# STMP3770 register map
Vendor: Freescale Semiconductor (NXP); Series: STMP37xx; File version: 1.0
CPU: other r0p0, little endian, no MPU, no FPU, 2 interrupt priority bits
Registers are 32-bit, read-write, reset 0x0 unless marked. A register's access mark holds for its fields unless they carry their own. Offsets are from the block's base; [hi:lo] are bit positions; {n}, {i} and the like mark numbered series.

## ICOLL — ICOLL 中断收集器，负责 ARM926EJ-S 中断请求(IRQ)与快速中断请求(FIQ)的优先级仲裁、向量分发及状态管理。注：SRC 1(JTAG调试)由ARM JTAG TAP控制器直接处理，不经过ICOLL。
Base 0x80000000
0x00 VECTOR — 中断向量地址寄存器，存储当前最高优先级中断的向量字地址，ISR 读取后可直接跳转。
  [31:2] IRQVECTOR — 当前中断向量字地址，占 bit[31:2]，对应 4 字节对齐的中断入口地址。
0x10 LEVELACK — 中断优先级确认寄存器，ISR 结束时写入对应位以清除指定优先级的中断服务状态。
  [3:0] IRQLEVELACK — 写 1<<level 确认对应优先级中断，可写 LEVEL0(0x1)、LEVEL1(0x2)、LEVEL2(0x4)、LEVEL3(0x8)。
    1=LEVEL0; 2=LEVEL1; 4=LEVEL2; 8=LEVEL3
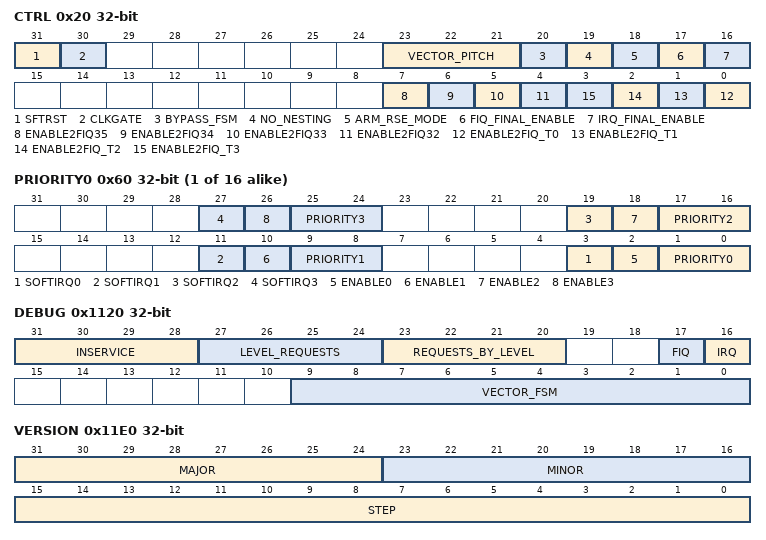
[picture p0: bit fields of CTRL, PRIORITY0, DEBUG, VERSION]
0x20 CTRL — 中断收集器全局控制寄存器，配置 IRQ/FIQ 总使能、嵌套策略、向量表间距及模块复位/时钟门控。
  [31] SFTRST — 软复位，IN_RESET 时对整个 ICOLL 模块执行软件复位。
    0=RUN; 1=IN_RESET
  [30] CLKGATE — 时钟门控，NO_CLOCKS 时关闭 ICOLL 模块时钟以节省功耗。
    0=RUN; 1=NO_CLOCKS
  [23:21] VECTOR_PITCH — 向量表项间距，枚举值 DEFAULT_BY4(默认)、BY4、BY8、BY12、BY16、BY20、BY24、BY28。
    0=DEFAULT_BY4; 1=BY4; 2=BY8; 3=BY12; 4=BY16; 5=BY20; 6=BY24; 7=BY28
  [20] BYPASS_FSM — FSM 旁路模式，BYPASS 时绕过内部向量状态机，用于调试或特殊操作模式。
    0=NORMAL; 1=BYPASS
  [19] NO_NESTING — 禁止中断嵌套，NO_NEST 时 ICOLL 不响应更低或同级优先级的新中断。
    0=NORMAL; 1=NO_NEST
  [18] ARM_RSE_MODE — ARM 读副作用模式，使能后读取 VECTOR 寄存器会触发 ICOLL 内部状态转换。
  [17] FIQ_FINAL_ENABLE — FIQ 总使能开关，ENABLE 时允许向 ARM 发出 FIQ 请求。
    0=DISABLE; 1=ENABLE
  [16] IRQ_FINAL_ENABLE — IRQ 总使能开关，ENABLE 时允许向 ARM 发出 IRQ 请求。
    0=DISABLE; 1=ENABLE
  [7] ENABLE2FIQ35 — 中断源 35(VDD18_BRNOUT)FIQ 路由使能，置位后对应中断改为 FIQ 方式送达 ARM 核。
  [6] ENABLE2FIQ34 — 中断源 34(VDDIO_BRNOUT)FIQ 路由使能，置位后对应中断改为 FIQ 方式送达 ARM 核。
  [5] ENABLE2FIQ33 — 中断源 33(VDDD_BRNOUT)FIQ 路由使能，置位后对应中断改为 FIQ 方式送达 ARM 核。
  [4] ENABLE2FIQ32 — 中断源 32(BATT_BRNOUT)FIQ 路由使能，置位后对应中断改为 FIQ 方式送达 ARM 核。
  [n] ENABLE2FIQ_T{n} (n=0..3) — Timer {n} FIQ 路由使能，置位后 Timer {n} 中断改为 FIQ 方式送达 ARM 核。
0x30 STAT — 中断收集器状态寄存器，反映当前正在服务的中断编号。
  [5:0] VECTOR_NUMBER — 当前正在服务的中断向量号，取值范围对应各中断源编号。
{0x40+0x10*i} RAW{i} (i=0..1) — 原始中断状态寄存器数组，每位反映对应中断源的原始硬件请求状态，不受使能控制影响。
  [31:0] RAW_IRQS — 32 位原始中断请求状态位图，1 表示对应中断源存在未处理硬件请求。
{0x60+0x10*i} PRIORITY{i} (i=0..15) — 中断优先级配置寄存器数组，每个寄存器管理 4 个中断源的优先级、使能及软件触发。
  [8n+3] SOFTIRQ{n} (n=0..3) — 中断源 {n} 的软件触发，FORCE_INTERRUPT 时强制产生软件中断请求。
    0=NO_INTERRUPT; 1=FORCE_INTERRUPT
  [8n+2] ENABLE{n} (n=0..3) — 中断源 {n} 的使能开关，ENABLE 时允许该中断参与仲裁。
    0=DISABLE; 1=ENABLE
  [8n+1:8n] PRIORITY{n} (n=0..3) — 中断源 {n} 的优先级，LEVEL0 最低，LEVEL3 最高。
    {v}=LEVEL{v} (v=0..3)
0x160 VBASE — 中断向量基地址寄存器，存放中断向量表的字地址，供 ICOLL 计算最终跳转地址。
  [31:2] TABLE_ADDRESS — 中断向量表基地址的字地址，占 bit[31:2]，低 2 位固定为 0 即 4 字节对齐。
0x1120 DEBUG ro — 中断收集器调试寄存器，暴露内部向量 FSM 状态、IRQ/FIQ 请求线及各优先级请求/服务状态。
  [31:28] INSERVICE — 当前正在服务的中断优先级位图，每位表示对应 LEVEL 是否处于服务中。
    1=LEVEL0; 2=LEVEL1; 4=LEVEL2; 8=LEVEL3
  [27:24] LEVEL_REQUESTS — 经门控后的每优先级中断请求汇总位图，每位表示对应 LEVEL 是否存在有效待处理请求。
    1=LEVEL0; 2=LEVEL1; 4=LEVEL2; 8=LEVEL3
  [23:20] REQUESTS_BY_LEVEL — 按优先级分类的原始中断请求位图，每位对应 LEVEL0~LEVEL3 是否有该级请求。
    1=LEVEL0; 2=LEVEL1; 4=LEVEL2; 8=LEVEL3
  [17] FIQ — FIQ 请求状态，FIQ_REQUESTED 表示当前存在向 ARM 的 FIQ 请求。
    0=NO_FIQ_REQUESTED; 1=FIQ_REQUESTED
  [16] IRQ — IRQ 请求状态，IRQ_REQUESTED 表示当前存在向 ARM 的 IRQ 请求。
    0=NO_IRQ_REQUESTED; 1=IRQ_REQUESTED
  [9:0] VECTOR_FSM — 向量 FSM 当前状态，枚举值覆盖 IDLE、PENDING、多周期处理及 ISR 运行等阶段。
    0=FSM_IDLE; 1=FSM_MULTICYCLE1; 2=FSM_MULTICYCLE2; 4=FSM_PENDING; 8=FSM_MULTICYCLE3; 16=FSM_MULTICYCLE4; 32=FSM_ISR_RUNNING1; 64=FSM_ISR_RUNNING2; 128=FSM_ISR_RUNNING3; 0x100=FSM_MULTICYCLE5; 0x200=FSM_MULTICYCLE6
0x1130 DBGREAD0 — 调试读镜像寄存器 0，用于调试时读取 ICOLL 内部总线或状态镜像值。
  [31:0] VALUE — 32 位调试镜像值，反映内部信号或总线数据的快照。
0x1140 DBGREAD1 — 调试读镜像寄存器 1，用于调试时读取 ICOLL 内部另一组总线或状态镜像值。
  [31:0] VALUE — 32 位调试镜像值，反映内部信号或总线数据的快照。
0x1150 DBGFLAG ro — 调试标志寄存器，提供 16 位调试标志位供内部状态标记或调试使用。
  [15:0] FLAG — 16 位调试标志位图，用于标记或读取内部调试状态。
{0x1160+0x10*i} DBGREQUEST{i} (i=0..1) — 调试请求寄存器数组，提供调试用的中断请求位镜像，用于观察或注入调试请求。
  [31:0] BITS — 32 位调试请求位图，反映或控制调试模式下的中断请求状态。
0x11E0 VERSION ro — 中断收集器版本寄存器，标识当前 ICOLL 硬件版本的主次及步进号。
  [31:24] MAJOR — 主版本号，标识当前硬件的主要版本。
  [23:16] MINOR — 次版本号，标识当前硬件的次要版本。
  [15:0] STEP — 步进版本号，标识当前硬件的步进修订。
